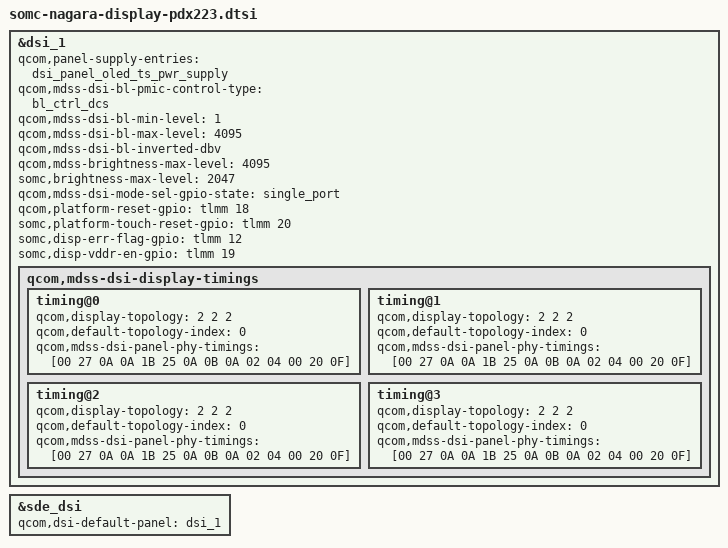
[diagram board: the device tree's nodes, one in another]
#include "dsi-panel-ana6707_amb650yl01-uhd-pdx223.dtsi"

&dsi_1 {
	qcom,panel-supply-entries = <&dsi_panel_oled_ts_pwr_supply>;
	qcom,mdss-dsi-bl-pmic-control-type = "bl_ctrl_dcs";
	qcom,mdss-dsi-bl-min-level = <1>;
	qcom,mdss-dsi-bl-max-level = <4095>;
	qcom,mdss-dsi-bl-inverted-dbv;
	qcom,mdss-brightness-max-level = <4095>;
	somc,brightness-max-level = <2047>;
	qcom,mdss-dsi-mode-sel-gpio-state = "single_port";

	qcom,platform-reset-gpio = <&tlmm 18 0>;
	somc,platform-touch-reset-gpio = <&tlmm 20 0>;
        somc,disp-err-flag-gpio = <&tlmm 12 0>;
	somc,disp-vddr-en-gpio = <&tlmm 19 0>;

	qcom,mdss-dsi-display-timings {
		timing@0 {
			qcom,display-topology = <2 2 2>;
			qcom,default-topology-index = <0>;
			qcom,mdss-dsi-panel-phy-timings = [00 27 0A 0A 1B 25 0A 0B 0A 02 04 00 20 0F];
		};
		timing@1 {
			qcom,display-topology = <2 2 2>;
			qcom,default-topology-index = <0>;
			qcom,mdss-dsi-panel-phy-timings = [00 27 0A 0A 1B 25 0A 0B 0A 02 04 00 20 0F];
		};
		timing@2 {
			qcom,display-topology = <2 2 2>;
			qcom,default-topology-index = <0>;
			qcom,mdss-dsi-panel-phy-timings = [00 27 0A 0A 1B 25 0A 0B 0A 02 04 00 20 0F];
		};
		timing@3 {
			qcom,display-topology = <2 2 2>;
			qcom,default-topology-index = <0>;
			qcom,mdss-dsi-panel-phy-timings = [00 27 0A 0A 1B 25 0A 0B 0A 02 04 00 20 0F];
		};
	};
};

&sde_dsi {
	qcom,dsi-default-panel = <&dsi_1>;
};
